# nrf54h20_engb_application register map
Vendor: Nordic Semiconductor; Series: nRF54h; File version: 1
CPU: CM33 r0p4, little endian, MPU, FPU, 3 interrupt priority bits, 480 interrupts, 8 SAU regions
Registers are 32-bit, read-write, reset 0x0 unless marked. A register's access mark holds for its fields unless they carry their own. Offsets are from the block's base; [hi:lo] are bit positions; lines under a group give offsets from that group; {n}, {i} and the like mark numbered series; 'fields as' and 'values as' point back to an identical list.

## ICACHE_S — Cache 0
Base 0xE0082000
Same registers: DCACHE_S 0xE0083000
0x00 TASKS_SAVE wo — Save the cache state to a retained memory space.
  [0] TASKS_SAVE
    1=Trigger task
0x04 TASKS_RESTORE wo — Restore the cache state from a retained memory space.
  [0] TASKS_RESTORE
    1=Trigger task
0x08 TASKS_INVALIDATECACHE wo — Invalidate the cache.
  [0] TASKS_INVALIDATECACHE
    1=Trigger task
0x0C TASKS_CLEANCACHE wo — Clean the cache.
  [0] TASKS_CLEANCACHE
    1=Trigger task
0x10 TASKS_FLUSHCACHE wo — Flush the cache.
  [0] TASKS_FLUSHCACHE
    1=Trigger task
0x14 TASKS_INVALIDATELINE wo — Invalidate the line.
  [0] TASKS_INVALIDATELINE
    1=Trigger task
0x18 TASKS_CLEANLINE wo — Clean the line.
  [0] TASKS_CLEANLINE
    1=Trigger task
0x1C TASKS_FLUSHLINE wo — Flush the line.
  [0] TASKS_FLUSHLINE
    1=Trigger task
0x20 TASKS_ERASE wo — Erase the cache.
  [0] TASKS_ERASE
    1=Trigger task
0x100 EVENTS_DONE — Save or Restore task is done.
  [0] EVENTS_DONE
    0=NotGenerated (Event not generated); 1=Generated (Event generated)
0x300 INTEN — Enable or disable interrupt
  [0] DONE — Enable or disable interrupt for event DONE
    0=Disabled; 1=Enabled
0x304 INTENSET — Enable interrupt
  [0] DONE — Write '1' to enable interrupt for event DONE
    on read: 0=Disabled (Read: Disabled); 1=Enabled (Read: Enabled) | on write: 1=Set (Enable)
0x308 INTENCLR — Disable interrupt
  [0] DONE — Write '1' to disable interrupt for event DONE
    on read: 0=Disabled (Read: Disabled); 1=Enabled (Read: Enabled) | on write: 1=Clear (Disable)
0x30C INTPEND ro — Pending interrupts
  [0] DONE — Read pending status of interrupt for event DONE
    on read: 0=NotPending (Read: Not pending); 1=Pending (Read: Pending)
0x400 STATUS ro — Status of the cache activities.
  [0] BUSY — Busy status.
    0=Ready (Activity is done and ready for the next activity.); 1=Busy (Activity is in progress.)
0x404 ENABLE — Enable cache.
  [0] ENABLE — Enable cache
    0=Disabled (Disable cache); 1=Enabled (Enable cache)
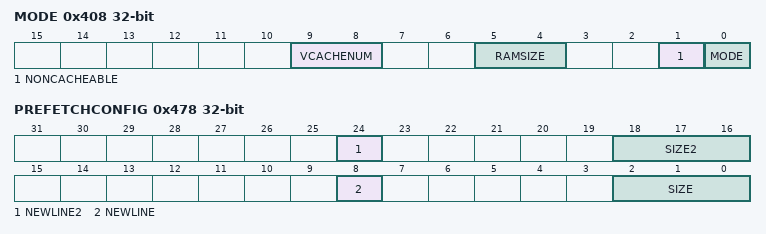
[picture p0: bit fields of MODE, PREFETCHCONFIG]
0x408 MODE — Cache mode.
  [9:8] VCACHENUM — Number of virtual cache regions.
    0=One (Whole cache is one region.); 1=Two (Whole cache is divided into two equal virtual regions.); 2=Four (Whole cache is divided into four equal virtual regions.); 3=Eight (Whole cache is divided into eight equal virtual regions.)
  [5:4] RAMSIZE
    0=All (All RAM is used for cache memory); 1=Half of the RAM is used for cache memory; 2=Quarter of the RAM is used for cache memory; 3=None of the RAM is used for cache memory
  [1] NONCACHEABLE — Enable non-cacheable cache miss feature
    0=Disabled (Non-cacheable cache miss feature is disabled); 1=Enabled (Non-cacheable cache miss feature is enabled)
  [0] MODE — Cache mode
    0=Cache mode; 1=Ram (RAM mode)
0x40C VCACHESEL — Select virtual cache region for profiling and maintenance.
  [2:0] REGION — Virtual region select.
0x410 LINEADDR — Memory address covered by the line to be maintained.
  [31:0] ADDR — Address.
0x414 PROFILING group — Unspecified
  0x00 ENABLE — Enable the profiling counters.
    [0] ENABLE — Enable the profiling counters
      0=Disable profiling; 1=Enable profiling
  0x04 CLEAR wo — Clear the profiling counters.
    [0] CLEAR — Clearing the profiling counters
      1=Clear the profiling counters
  0x08 HIT ro — The cache hit counter for cache region.
    [31:0] HITS — Number of cache hits
  0x0C MISS ro — The cache miss counter for cache region.
    [31:0] MISSES — Number of cache misses
  0x10 LMISS ro — The cache line miss counter for cache region.
    [31:0] LMISSES — Number of cache line misses
  0x14 READS ro — Number of reads for cache region.
  0x18 WRITES ro — Number of writes for cache region.
0x430 DEBUGLOCK rw-once — Lock debug mode.
  [0] DEBUGLOCK — Lock debug mode
    0=Unlocked (Debug mode unlocked); 1=Locked (Debug mode locked. Ignores any other value written.)
0x434 WRITELOCK — Lock cache updates.
  [0] WRITELOCK — Lock cache updates
    0=Unlocked (Cache updates unlocked); 1=Locked (Cache updates locked)
{0x438+4i} VCACHEOWNER[{i}] (i=0..15) — Description collection: Cache owners for the virtual cache regions.
  [2:0] REGION — Owner [n] is mapped to this VCACHE region.
0x478 PREFETCHCONFIG — Prefetch Policy.
  [24] NEWLINE2 — Allow speculative prefetch continue onto a new line.
    0=Disabled (Speculative prefetch continue onto a new line is disabled); 1=Enabled (Speculative prefetch continue onto a new line is enabled)
  [18:16] SIZE2 — Prefetch size 2
  [8] NEWLINE — Allow speculative prefetch continue onto a new line.
    values as NEWLINE2
  [2:0] SIZE — Prefetch size
0x47C LINEADDRNS — Same as register LINEADDR, but for non-secure access. The bit 28 of the address is hard coded to 0.
  [31:0] ADDR — Address.
0x480 COHERENCYSTATUS group — Unspecified
  0x00 INVALIDATELINE ro read-has-side-effects — Performs an atomic read of the STATUS registers and triggering the Invalidate operation; accessible for non-secure access as well.
    [0] BUSY — Status
      0=Ready (STATUS.READY was ready); 1=Busy (STATUS.READY was busy)
  0x04 CLEANLINE ro read-has-side-effects — Performs an atomic read of the STATUS registers and triggering the Clean operation; accessible for non-secure access as well.
    fields as COHERENCYSTATUS.INVALIDATELINE
  0x08 FLUSHLINE ro read-has-side-effects — Performs an atomic read of the STATUS registers and triggering the Flush operation; accessible for non-secure access as well.
    fields as COHERENCYSTATUS.INVALIDATELINE

## Notices in the file
Copyright (c) 2010 - 2024, Nordic Semiconductor ASA
All rights reserved.
Redistribution and use in source and binary forms, with or without modification,
are permitted provided that the following conditions are met:
1. Redistributions of source code must retain the above copyright notice, this
list of conditions and the following disclaimer.
2. Redistributions in binary form, except as embedded into a Nordic
Semiconductor ASA integrated circuit in a product or a software update for
such product, must reproduce the above copyright notice, this list of
conditions and the following disclaimer in the documentation and/or other
materials provided with the distribution.
3. Neither the name of Nordic Semiconductor ASA nor the names of its
contributors may be used to endorse or promote products derived from this
software without specific prior written permission.
4. This software, with or without modification, must only be used with a
Nordic Semiconductor ASA integrated circuit.
5. Any software provided in binary form under this license must not be reverse
engineered, decompiled, modified and/or disassembled.
THIS SOFTWARE IS PROVIDED BY NORDIC SEMICONDUCTOR ASA "AS IS" AND ANY EXPRESS
OR IMPLIED WARRANTIES, INCLUDING, BUT NOT LIMITED TO, THE IMPLIED WARRANTIES
OF MERCHANTABILITY, NONINFRINGEMENT, AND FITNESS FOR A PARTICULAR PURPOSE ARE
DISCLAIMED. IN NO EVENT SHALL NORDIC SEMICONDUCTOR ASA OR CONTRIBUTORS BE
LIABLE FOR ANY DIRECT, INDIRECT, INCIDENTAL, SPECIAL, EXEMPLARY, OR
CONSEQUENTIAL DAMAGES (INCLUDING, BUT NOT LIMITED TO, PROCUREMENT OF SUBSTITUTE
GOODS OR SERVICES; LOSS OF USE, DATA, OR PROFITS; OR BUSINESS INTERRUPTION)
HOWEVER CAUSED AND ON ANY THEORY OF LIABILITY, WHETHER IN CONTRACT, STRICT
LIABILITY, OR TORT (INCLUDING NEGLIGENCE OR OTHERWISE) ARISING IN ANY WAY OUT
OF THE USE OF THIS SOFTWARE, EVEN IF ADVISED OF THE POSSIBILITY OF SUCH DAMAGE.
